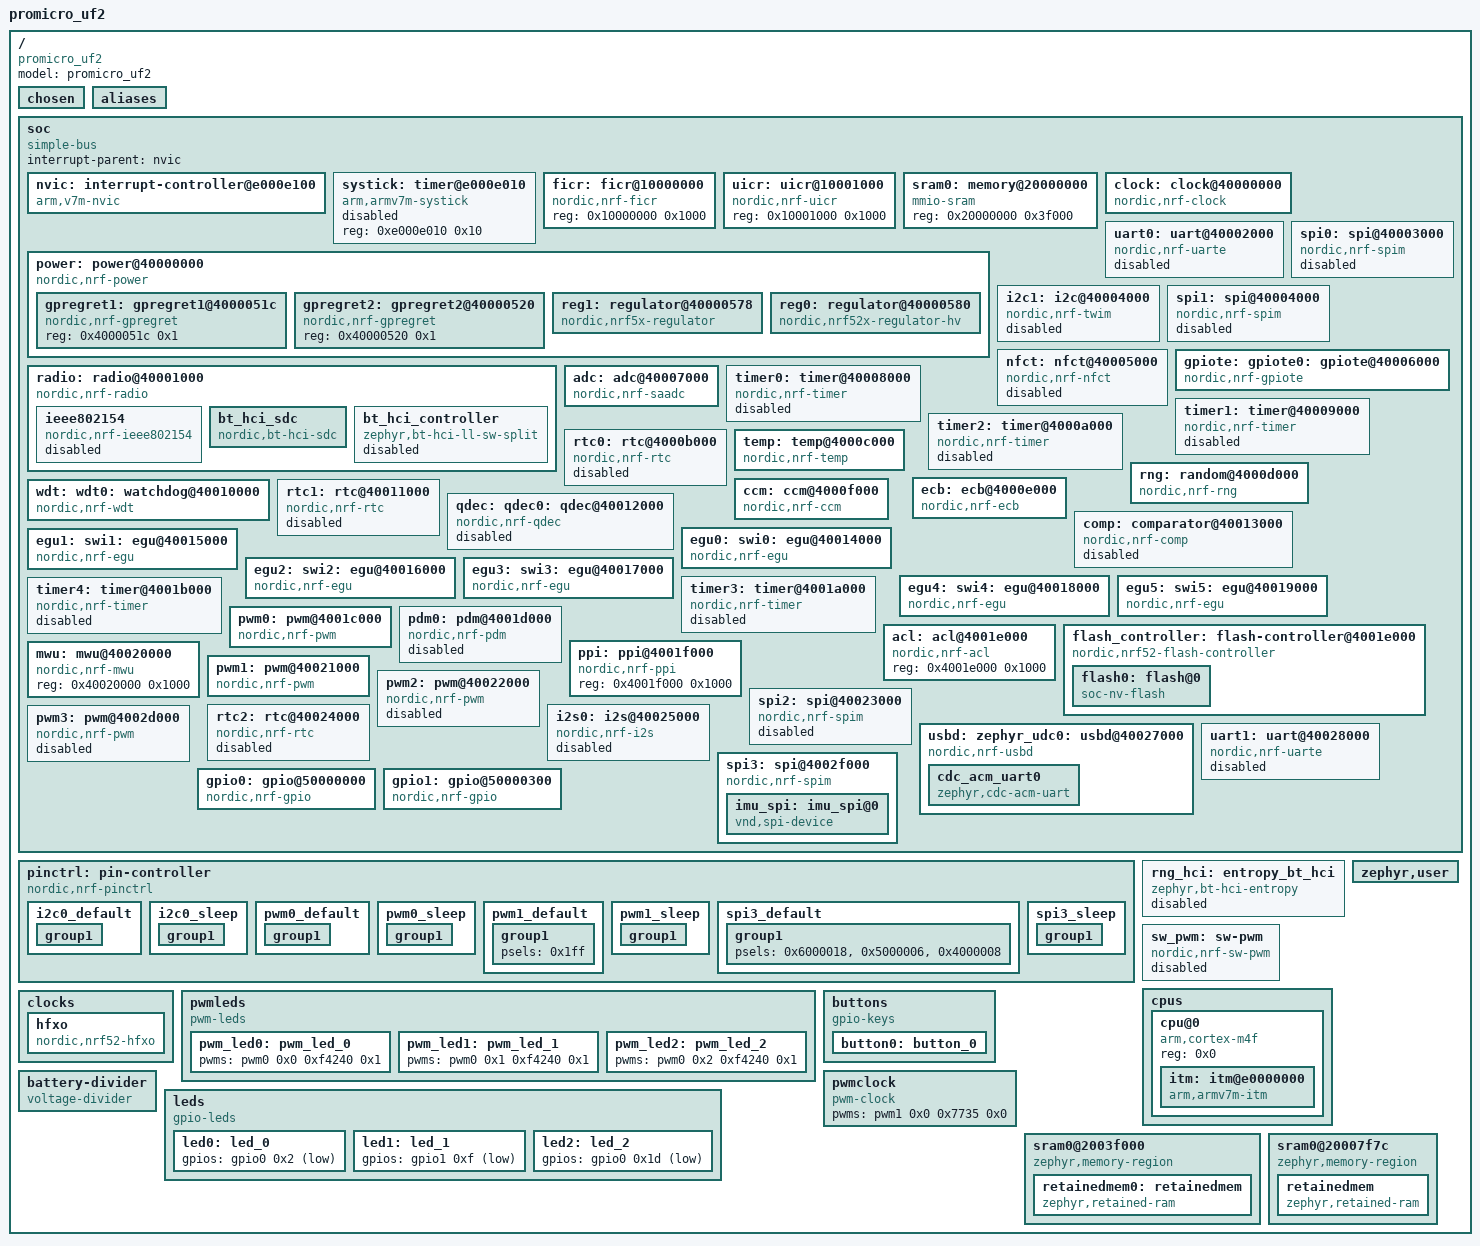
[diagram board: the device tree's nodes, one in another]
/dts-v1/;

/* node '/' defined in zephyr\dts\common\skeleton.dtsi:9 */
/ {
	#address-cells = < 0x1 >;    /* in zephyr\dts\common\skeleton.dtsi:10 */
	#size-cells = < 0x1 >;       /* in zephyr\dts\common\skeleton.dtsi:11 */
	model = "promicro_uf2";      /* in F:/nRF-Firmware-DqEdit/SlimeVR-Tracker-nRF/boards/nekumori/sakuranrf/sakuranrf_uf2.dts:71 */
	compatible = "promicro_uf2"; /* in F:/nRF-Firmware-DqEdit/SlimeVR-Tracker-nRF/boards/nekumori/sakuranrf/sakuranrf_uf2.dts:72 */

	/* node '/chosen' defined in zephyr\dts\common\skeleton.dtsi:12 */
	chosen {
		zephyr,bt-hci = &bt_hci_sdc;                 /* in zephyr\dts\arm\nordic\nrf52833.dtsi:14 */
		zephyr,entropy = &rng;                       /* in zephyr\dts\arm\nordic\nrf52833.dtsi:15 */
		zephyr,flash-controller = &flash_controller; /* in zephyr\dts\arm\nordic\nrf52833.dtsi:16 */
		zephyr,sram = &sram0;                        /* in F:/nRF-Firmware-DqEdit/SlimeVR-Tracker-nRF/boards/nekumori/sakuranrf/sakuranrf_uf2.dts:75 */
		zephyr,flash = &flash0;                      /* in F:/nRF-Firmware-DqEdit/SlimeVR-Tracker-nRF/boards/nekumori/sakuranrf/sakuranrf_uf2.dts:76 */
		zephyr,console = &cdc_acm_uart0;             /* in F:/nRF-Firmware-DqEdit/SlimeVR-Tracker-nRF/boards/nekumori/sakuranrf/sakuranrf_uf2.dts:77 */
		zephyr,shell-uart = &cdc_acm_uart0;          /* in F:/nRF-Firmware-DqEdit/SlimeVR-Tracker-nRF/boards/nekumori/sakuranrf/sakuranrf_uf2.dts:78 */
	};

	/* node '/aliases' defined in zephyr\dts\common\skeleton.dtsi:13 */
	aliases {
		sw0 = &button0;                    /* in F:/nRF-Firmware-DqEdit/SlimeVR-Tracker-nRF/boards/nekumori/sakuranrf/sakuranrf_uf2_chrysalis.dts:54 */
		pwm-led0 = &pwm_led0;              /* in F:/nRF-Firmware-DqEdit/SlimeVR-Tracker-nRF/boards/nekumori/sakuranrf/sakuranrf_uf2_chrysalis.dts:55 */
		pwm-led1 = &pwm_led1;              /* in F:/nRF-Firmware-DqEdit/SlimeVR-Tracker-nRF/boards/nekumori/sakuranrf/sakuranrf_uf2_chrysalis.dts:56 */
		pwm-led2 = &pwm_led2;              /* in F:/nRF-Firmware-DqEdit/SlimeVR-Tracker-nRF/boards/nekumori/sakuranrf/sakuranrf_uf2_chrysalis.dts:57 */
		led0 = &led0;                      /* in F:/nRF-Firmware-DqEdit/SlimeVR-Tracker-nRF/boards/nekumori/sakuranrf/sakuranrf_uf2_chrysalis.dts:58 */
		led1 = &led1;                      /* in F:/nRF-Firmware-DqEdit/SlimeVR-Tracker-nRF/boards/nekumori/sakuranrf/sakuranrf_uf2_chrysalis.dts:59 */
		led2 = &led2;                      /* in F:/nRF-Firmware-DqEdit/SlimeVR-Tracker-nRF/boards/nekumori/sakuranrf/sakuranrf_uf2_chrysalis.dts:60 */
		retainedmemdevice = &retainedmem0; /* in F:/nRF-Firmware-DqEdit/SlimeVR-Tracker-nRF/socs/nrf52833_chrysalis.overlay:27 */
	};

	/* node '/soc' defined in zephyr\dts\arm\armv7-m.dtsi:6 */
	soc {
		#address-cells = < 0x1 >;     /* in zephyr\dts\arm\armv7-m.dtsi:7 */
		#size-cells = < 0x1 >;        /* in zephyr\dts\arm\armv7-m.dtsi:8 */
		interrupt-parent = < &nvic >; /* in zephyr\dts\arm\armv7-m.dtsi:10 */
		ranges;                       /* in zephyr\dts\arm\armv7-m.dtsi:11 */
		compatible = "simple-bus";    /* in zephyr\dts\arm\nordic\nrf52833_qiaa.dtsi:20 */

		/* node '/soc/interrupt-controller@e000e100' defined in zephyr\dts\arm\armv7-m.dtsi:13 */
		nvic: interrupt-controller@e000e100 {
			#address-cells = < 0x1 >;            /* in zephyr\dts\arm\armv7-m.dtsi:14 */
			compatible = "arm,v7m-nvic";         /* in zephyr\dts\arm\armv7-m.dtsi:15 */
			reg = < 0xe000e100 0xc00 >;          /* in zephyr\dts\arm\armv7-m.dtsi:16 */
			interrupt-controller;                /* in zephyr\dts\arm\armv7-m.dtsi:17 */
			#interrupt-cells = < 0x2 >;          /* in zephyr\dts\arm\armv7-m.dtsi:18 */
			arm,num-irq-priority-bits = < 0x3 >; /* in zephyr\dts\arm\nordic\nrf52833.dtsi:576 */
			phandle = < 0x1 >;                   /* in zephyr\dts\arm\armv7-m.dtsi:10 */
		};

		/* node '/soc/timer@e000e010' defined in zephyr\dts\arm\armv7-m.dtsi:21 */
		systick: timer@e000e010 {
			compatible = "arm,armv7m-systick"; /* in zephyr\dts\arm\armv7-m.dtsi:22 */
			reg = < 0xe000e010 0x10 >;         /* in zephyr\dts\arm\armv7-m.dtsi:23 */
			status = "disabled";               /* in zephyr\dts\arm\nordic\nrf52833.dtsi:581 */
		};

		/* node '/soc/ficr@10000000' defined in zephyr\dts\arm\nordic\nrf52833.dtsi:48 */
		ficr: ficr@10000000 {
			compatible = "nordic,nrf-ficr"; /* in zephyr\dts\arm\nordic\nrf52833.dtsi:49 */
			reg = < 0x10000000 0x1000 >;    /* in zephyr\dts\arm\nordic\nrf52833.dtsi:50 */
			#nordic,ficr-cells = < 0x1 >;   /* in zephyr\dts\arm\nordic\nrf52833.dtsi:51 */
			status = "okay";                /* in zephyr\dts\arm\nordic\nrf52833.dtsi:52 */
		};

		/* node '/soc/uicr@10001000' defined in zephyr\dts\arm\nordic\nrf52833.dtsi:55 */
		uicr: uicr@10001000 {
			compatible = "nordic,nrf-uicr"; /* in zephyr\dts\arm\nordic\nrf52833.dtsi:56 */
			reg = < 0x10001000 0x1000 >;    /* in zephyr\dts\arm\nordic\nrf52833.dtsi:57 */
			status = "okay";                /* in zephyr\dts\arm\nordic\nrf52833.dtsi:58 */
		};

		/* node '/soc/memory@20000000' defined in zephyr\dts\arm\nordic\nrf52833.dtsi:61 */
		sram0: memory@20000000 {
			compatible = "mmio-sram";     /* in zephyr\dts\arm\nordic\nrf52833.dtsi:62 */
			reg = < 0x20000000 0x3f000 >; /* in F:/nRF-Firmware-DqEdit/SlimeVR-Tracker-nRF/socs/nrf52833_chrysalis.overlay:33 */
		};

		/* node '/soc/clock@40000000' defined in zephyr\dts\arm\nordic\nrf52833.dtsi:65 */
		clock: clock@40000000 {
			compatible = "nordic,nrf-clock"; /* in zephyr\dts\arm\nordic\nrf52833.dtsi:66 */
			reg = < 0x40000000 0x1000 >;     /* in zephyr\dts\arm\nordic\nrf52833.dtsi:67 */
			interrupts = < 0x0 0x1 >;        /* in zephyr\dts\arm\nordic\nrf52833.dtsi:68 */
			status = "okay";                 /* in zephyr\dts\arm\nordic\nrf52833.dtsi:69 */
		};

		/* node '/soc/power@40000000' defined in zephyr\dts\arm\nordic\nrf52833.dtsi:72 */
		power: power@40000000 {
			compatible = "nordic,nrf-power"; /* in zephyr\dts\arm\nordic\nrf52833.dtsi:73 */
			reg = < 0x40000000 0x1000 >;     /* in zephyr\dts\arm\nordic\nrf52833.dtsi:74 */
			interrupts = < 0x0 0x1 >;        /* in zephyr\dts\arm\nordic\nrf52833.dtsi:75 */
			status = "okay";                 /* in zephyr\dts\arm\nordic\nrf52833.dtsi:76 */
			#address-cells = < 0x1 >;        /* in zephyr\dts\arm\nordic\nrf52833.dtsi:77 */
			#size-cells = < 0x1 >;           /* in zephyr\dts\arm\nordic\nrf52833.dtsi:78 */

			/* node '/soc/power@40000000/gpregret1@4000051c' defined in zephyr\dts\arm\nordic\nrf52833.dtsi:80 */
			gpregret1: gpregret1@4000051c {
				#address-cells = < 0x1 >;           /* in zephyr\dts\arm\nordic\nrf52833.dtsi:81 */
				#size-cells = < 0x1 >;              /* in zephyr\dts\arm\nordic\nrf52833.dtsi:82 */
				compatible = "nordic,nrf-gpregret"; /* in zephyr\dts\arm\nordic\nrf52833.dtsi:83 */
				reg = < 0x4000051c 0x1 >;           /* in zephyr\dts\arm\nordic\nrf52833.dtsi:84 */
				status = "okay";                    /* in zephyr\dts\arm\nordic\nrf52833.dtsi:85 */
			};

			/* node '/soc/power@40000000/gpregret2@40000520' defined in zephyr\dts\arm\nordic\nrf52833.dtsi:88 */
			gpregret2: gpregret2@40000520 {
				#address-cells = < 0x1 >;           /* in zephyr\dts\arm\nordic\nrf52833.dtsi:89 */
				#size-cells = < 0x1 >;              /* in zephyr\dts\arm\nordic\nrf52833.dtsi:90 */
				compatible = "nordic,nrf-gpregret"; /* in zephyr\dts\arm\nordic\nrf52833.dtsi:91 */
				reg = < 0x40000520 0x1 >;           /* in zephyr\dts\arm\nordic\nrf52833.dtsi:92 */
				status = "okay";                    /* in zephyr\dts\arm\nordic\nrf52833.dtsi:93 */
			};

			/* node '/soc/power@40000000/regulator@40000578' defined in zephyr\dts\arm\nordic\nrf52833.dtsi:96 */
			reg1: regulator@40000578 {
				compatible = "nordic,nrf5x-regulator"; /* in zephyr\dts\arm\nordic\nrf52833.dtsi:97 */
				reg = < 0x40000578 0x1 >;              /* in zephyr\dts\arm\nordic\nrf52833.dtsi:98 */
				regulator-name = "REG1";               /* in zephyr\dts\arm\nordic\nrf52833.dtsi:99 */
				regulator-initial-mode = < 0x1 >;      /* in F:/nRF-Firmware-DqEdit/SlimeVR-Tracker-nRF/boards/nekumori/sakuranrf/sakuranrf_uf2.dts:129 */
			};

			/* node '/soc/power@40000000/regulator@40000580' defined in zephyr\dts\arm\nordic\nrf52833.dtsi:103 */
			reg0: regulator@40000580 {
				compatible = "nordic,nrf52x-regulator-hv"; /* in zephyr\dts\arm\nordic\nrf52833.dtsi:104 */
				reg = < 0x40000580 0x1 >;                  /* in zephyr\dts\arm\nordic\nrf52833.dtsi:105 */
				regulator-name = "REG0";                   /* in zephyr\dts\arm\nordic\nrf52833.dtsi:106 */
				status = "okay";                           /* in F:/nRF-Firmware-DqEdit/SlimeVR-Tracker-nRF/boards/nekumori/sakuranrf/sakuranrf_uf2.dts:125 */
			};
		};

		/* node '/soc/radio@40001000' defined in zephyr\dts\arm\nordic\nrf52833.dtsi:111 */
		radio: radio@40001000 {
			compatible = "nordic,nrf-radio"; /* in zephyr\dts\arm\nordic\nrf52833.dtsi:112 */
			reg = < 0x40001000 0x1000 >;     /* in zephyr\dts\arm\nordic\nrf52833.dtsi:113 */
			interrupts = < 0x1 0x1 >;        /* in zephyr\dts\arm\nordic\nrf52833.dtsi:114 */
			status = "okay";                 /* in zephyr\dts\arm\nordic\nrf52833.dtsi:115 */
			dfe-supported;                   /* in zephyr\dts\arm\nordic\nrf52833.dtsi:116 */
			ieee802154-supported;            /* in zephyr\dts\arm\nordic\nrf52833.dtsi:117 */
			ble-2mbps-supported;             /* in zephyr\dts\arm\nordic\nrf52833.dtsi:118 */
			ble-coded-phy-supported;         /* in zephyr\dts\arm\nordic\nrf52833.dtsi:119 */
			tx-high-power-supported;         /* in zephyr\dts\arm\nordic\nrf52833.dtsi:120 */

			/* node '/soc/radio@40001000/ieee802154' defined in zephyr\dts\arm\nordic\nrf52833.dtsi:122 */
			ieee802154: ieee802154 {
				compatible = "nordic,nrf-ieee802154"; /* in zephyr\dts\arm\nordic\nrf52833.dtsi:123 */
				status = "disabled";                  /* in zephyr\dts\arm\nordic\nrf52833.dtsi:124 */
			};

			/* node '/soc/radio@40001000/bt_hci_sdc' defined in zephyr\dts\arm\nordic\nrf52833.dtsi:127 */
			bt_hci_sdc: bt_hci_sdc {
				compatible = "nordic,bt-hci-sdc"; /* in zephyr\dts\arm\nordic\nrf52833.dtsi:128 */
				status = "okay";                  /* in zephyr\dts\arm\nordic\nrf52833.dtsi:129 */
			};

			/* node '/soc/radio@40001000/bt_hci_controller' defined in zephyr\dts\arm\nordic\nrf52833.dtsi:131 */
			bt_hci_controller: bt_hci_controller {
				compatible = "zephyr,bt-hci-ll-sw-split"; /* in zephyr\dts\arm\nordic\nrf52833.dtsi:132 */
				status = "disabled";                      /* in zephyr\dts\arm\nordic\nrf52833.dtsi:133 */
			};
		};

		/* node '/soc/uart@40002000' defined in zephyr\dts\arm\nordic\nrf52833.dtsi:137 */
		uart0: uart@40002000 {
			compatible = "nordic,nrf-uarte"; /* in zephyr\dts\arm\nordic\nrf52833.dtsi:140 */
			reg = < 0x40002000 0x1000 >;     /* in zephyr\dts\arm\nordic\nrf52833.dtsi:141 */
			interrupts = < 0x2 0x1 >;        /* in zephyr\dts\arm\nordic\nrf52833.dtsi:142 */
			status = "disabled";             /* in zephyr\dts\arm\nordic\nrf52833.dtsi:143 */
		};

		/* node '/soc/spi@40003000' defined in zephyr\dts\arm\nordic\nrf52833.dtsi:164 */
		spi0: spi@40003000 {
			compatible = "nordic,nrf-spim"; /* in zephyr\dts\arm\nordic\nrf52833.dtsi:172 */
			#address-cells = < 0x1 >;       /* in zephyr\dts\arm\nordic\nrf52833.dtsi:173 */
			#size-cells = < 0x0 >;          /* in zephyr\dts\arm\nordic\nrf52833.dtsi:174 */
			reg = < 0x40003000 0x1000 >;    /* in zephyr\dts\arm\nordic\nrf52833.dtsi:175 */
			interrupts = < 0x3 0x1 >;       /* in zephyr\dts\arm\nordic\nrf52833.dtsi:176 */
			max-frequency = < 0x7a1200 >;   /* in zephyr\dts\arm\nordic\nrf52833.dtsi:177 */
			easydma-maxcnt-bits = < 0x10 >; /* in zephyr\dts\arm\nordic\nrf52833.dtsi:178 */
			status = "disabled";            /* in zephyr\dts\arm\nordic\nrf52833.dtsi:179 */
		};

		/* node '/soc/i2c@40004000' defined in zephyr\dts\arm\nordic\nrf52833.dtsi:182 */
		i2c1: i2c@40004000 {
			compatible = "nordic,nrf-twim"; /* in zephyr\dts\arm\nordic\nrf52833.dtsi:190 */
			#address-cells = < 0x1 >;       /* in zephyr\dts\arm\nordic\nrf52833.dtsi:191 */
			#size-cells = < 0x0 >;          /* in zephyr\dts\arm\nordic\nrf52833.dtsi:192 */
			reg = < 0x40004000 0x1000 >;    /* in zephyr\dts\arm\nordic\nrf52833.dtsi:193 */
			interrupts = < 0x4 0x1 >;       /* in zephyr\dts\arm\nordic\nrf52833.dtsi:194 */
			easydma-maxcnt-bits = < 0x10 >; /* in zephyr\dts\arm\nordic\nrf52833.dtsi:195 */
			status = "disabled";            /* in zephyr\dts\arm\nordic\nrf52833.dtsi:196 */
			zephyr,pm-device-runtime-auto;  /* in zephyr\dts\arm\nordic\nrf52833.dtsi:197 */
		};

		/* node '/soc/spi@40004000' defined in zephyr\dts\arm\nordic\nrf52833.dtsi:200 */
		spi1: spi@40004000 {
			compatible = "nordic,nrf-spim"; /* in zephyr\dts\arm\nordic\nrf52833.dtsi:208 */
			#address-cells = < 0x1 >;       /* in zephyr\dts\arm\nordic\nrf52833.dtsi:209 */
			#size-cells = < 0x0 >;          /* in zephyr\dts\arm\nordic\nrf52833.dtsi:210 */
			reg = < 0x40004000 0x1000 >;    /* in zephyr\dts\arm\nordic\nrf52833.dtsi:211 */
			interrupts = < 0x4 0x1 >;       /* in zephyr\dts\arm\nordic\nrf52833.dtsi:212 */
			max-frequency = < 0x7a1200 >;   /* in zephyr\dts\arm\nordic\nrf52833.dtsi:213 */
			easydma-maxcnt-bits = < 0x10 >; /* in zephyr\dts\arm\nordic\nrf52833.dtsi:214 */
			status = "disabled";            /* in zephyr\dts\arm\nordic\nrf52833.dtsi:215 */
		};

		/* node '/soc/nfct@40005000' defined in zephyr\dts\arm\nordic\nrf52833.dtsi:218 */
		nfct: nfct@40005000 {
			compatible = "nordic,nrf-nfct"; /* in zephyr\dts\arm\nordic\nrf52833.dtsi:219 */
			reg = < 0x40005000 0x1000 >;    /* in zephyr\dts\arm\nordic\nrf52833.dtsi:220 */
			interrupts = < 0x5 0x1 >;       /* in zephyr\dts\arm\nordic\nrf52833.dtsi:221 */
			status = "disabled";            /* in F:/nRF-Firmware-DqEdit/SlimeVR-Tracker-nRF/boards/nekumori/sakuranrf/sakuranrf_uf2.dts:199 */
		};

		/* node '/soc/gpiote@40006000' defined in zephyr\dts\arm\nordic\nrf52833.dtsi:225 */
		gpiote: gpiote0: gpiote@40006000 {
			compatible = "nordic,nrf-gpiote"; /* in zephyr\dts\arm\nordic\nrf52833.dtsi:226 */
			reg = < 0x40006000 0x1000 >;      /* in zephyr\dts\arm\nordic\nrf52833.dtsi:227 */
			interrupts = < 0x6 0x5 >;         /* in zephyr\dts\arm\nordic\nrf52833.dtsi:228 */
			instance = < 0x0 >;               /* in zephyr\dts\arm\nordic\nrf52833.dtsi:230 */
			status = "okay";                  /* in F:/nRF-Firmware-DqEdit/SlimeVR-Tracker-nRF/boards/nekumori/sakuranrf/sakuranrf_uf2.dts:137 */
			phandle = < 0x9 >;                /* in zephyr\dts\arm\nordic\nrf52833.dtsi:558 */
		};

		/* node '/soc/adc@40007000' defined in zephyr\dts\arm\nordic\nrf52833.dtsi:233 */
		adc: adc@40007000 {
			compatible = "nordic,nrf-saadc"; /* in zephyr\dts\arm\nordic\nrf52833.dtsi:234 */
			reg = < 0x40007000 0x1000 >;     /* in zephyr\dts\arm\nordic\nrf52833.dtsi:235 */
			interrupts = < 0x7 0x1 >;        /* in zephyr\dts\arm\nordic\nrf52833.dtsi:236 */
			#io-channel-cells = < 0x1 >;     /* in zephyr\dts\arm\nordic\nrf52833.dtsi:238 */
			zephyr,pm-device-runtime-auto;   /* in zephyr\dts\arm\nordic\nrf52833.dtsi:239 */
			status = "okay";                 /* in F:/nRF-Firmware-DqEdit/SlimeVR-Tracker-nRF/boards/nekumori/sakuranrf/sakuranrf_uf2.dts:133 */
			phandle = < 0xe >;               /* in F:/nRF-Firmware-DqEdit/SlimeVR-Tracker-nRF/boards/nekumori/sakuranrf/sakuranrf_uf2.dts:110 */
		};

		/* node '/soc/timer@40008000' defined in zephyr\dts\arm\nordic\nrf52833.dtsi:242 */
		timer0: timer@40008000 {
			compatible = "nordic,nrf-timer"; /* in zephyr\dts\arm\nordic\nrf52833.dtsi:243 */
			status = "disabled";             /* in zephyr\dts\arm\nordic\nrf52833.dtsi:244 */
			reg = < 0x40008000 0x1000 >;     /* in zephyr\dts\arm\nordic\nrf52833.dtsi:245 */
			cc-num = < 0x4 >;                /* in zephyr\dts\arm\nordic\nrf52833.dtsi:246 */
			max-bit-width = < 0x20 >;        /* in zephyr\dts\arm\nordic\nrf52833.dtsi:247 */
			interrupts = < 0x8 0x1 >;        /* in zephyr\dts\arm\nordic\nrf52833.dtsi:248 */
			prescaler = < 0x0 >;             /* in zephyr\dts\arm\nordic\nrf52833.dtsi:249 */
		};

		/* node '/soc/timer@40009000' defined in zephyr\dts\arm\nordic\nrf52833.dtsi:252 */
		timer1: timer@40009000 {
			compatible = "nordic,nrf-timer"; /* in zephyr\dts\arm\nordic\nrf52833.dtsi:253 */
			status = "disabled";             /* in zephyr\dts\arm\nordic\nrf52833.dtsi:254 */
			reg = < 0x40009000 0x1000 >;     /* in zephyr\dts\arm\nordic\nrf52833.dtsi:255 */
			cc-num = < 0x4 >;                /* in zephyr\dts\arm\nordic\nrf52833.dtsi:256 */
			max-bit-width = < 0x20 >;        /* in zephyr\dts\arm\nordic\nrf52833.dtsi:257 */
			interrupts = < 0x9 0x1 >;        /* in zephyr\dts\arm\nordic\nrf52833.dtsi:258 */
			prescaler = < 0x0 >;             /* in zephyr\dts\arm\nordic\nrf52833.dtsi:259 */
			phandle = < 0xa >;               /* in zephyr\dts\vendor\nordic\nrf_common.dtsi:42 */
		};

		/* node '/soc/timer@4000a000' defined in zephyr\dts\arm\nordic\nrf52833.dtsi:262 */
		timer2: timer@4000a000 {
			compatible = "nordic,nrf-timer"; /* in zephyr\dts\arm\nordic\nrf52833.dtsi:263 */
			status = "disabled";             /* in zephyr\dts\arm\nordic\nrf52833.dtsi:264 */
			reg = < 0x4000a000 0x1000 >;     /* in zephyr\dts\arm\nordic\nrf52833.dtsi:265 */
			cc-num = < 0x4 >;                /* in zephyr\dts\arm\nordic\nrf52833.dtsi:266 */
			max-bit-width = < 0x20 >;        /* in zephyr\dts\arm\nordic\nrf52833.dtsi:267 */
			interrupts = < 0xa 0x1 >;        /* in zephyr\dts\arm\nordic\nrf52833.dtsi:268 */
			prescaler = < 0x0 >;             /* in zephyr\dts\arm\nordic\nrf52833.dtsi:269 */
		};

		/* node '/soc/rtc@4000b000' defined in zephyr\dts\arm\nordic\nrf52833.dtsi:272 */
		rtc0: rtc@4000b000 {
			compatible = "nordic,nrf-rtc"; /* in zephyr\dts\arm\nordic\nrf52833.dtsi:273 */
			reg = < 0x4000b000 0x1000 >;   /* in zephyr\dts\arm\nordic\nrf52833.dtsi:274 */
			cc-num = < 0x3 >;              /* in zephyr\dts\arm\nordic\nrf52833.dtsi:275 */
			interrupts = < 0xb 0x1 >;      /* in zephyr\dts\arm\nordic\nrf52833.dtsi:276 */
			status = "disabled";           /* in zephyr\dts\arm\nordic\nrf52833.dtsi:277 */
			clock-frequency = < 0x8000 >;  /* in zephyr\dts\arm\nordic\nrf52833.dtsi:278 */
			prescaler = < 0x1 >;           /* in zephyr\dts\arm\nordic\nrf52833.dtsi:279 */
		};

		/* node '/soc/temp@4000c000' defined in zephyr\dts\arm\nordic\nrf52833.dtsi:282 */
		temp: temp@4000c000 {
			compatible = "nordic,nrf-temp"; /* in zephyr\dts\arm\nordic\nrf52833.dtsi:283 */
			reg = < 0x4000c000 0x1000 >;    /* in zephyr\dts\arm\nordic\nrf52833.dtsi:284 */
			interrupts = < 0xc 0x1 >;       /* in zephyr\dts\arm\nordic\nrf52833.dtsi:285 */
			status = "okay";                /* in zephyr\dts\arm\nordic\nrf52833.dtsi:286 */
		};

		/* node '/soc/random@4000d000' defined in zephyr\dts\arm\nordic\nrf52833.dtsi:289 */
		rng: random@4000d000 {
			compatible = "nordic,nrf-rng"; /* in zephyr\dts\arm\nordic\nrf52833.dtsi:290 */
			reg = < 0x4000d000 0x1000 >;   /* in zephyr\dts\arm\nordic\nrf52833.dtsi:291 */
			interrupts = < 0xd 0x1 >;      /* in zephyr\dts\arm\nordic\nrf52833.dtsi:292 */
			status = "okay";               /* in zephyr\dts\arm\nordic\nrf52833.dtsi:293 */
		};

		/* node '/soc/ecb@4000e000' defined in zephyr\dts\arm\nordic\nrf52833.dtsi:296 */
		ecb: ecb@4000e000 {
			compatible = "nordic,nrf-ecb"; /* in zephyr\dts\arm\nordic\nrf52833.dtsi:297 */
			reg = < 0x4000e000 0x1000 >;   /* in zephyr\dts\arm\nordic\nrf52833.dtsi:298 */
			interrupts = < 0xe 0x1 >;      /* in zephyr\dts\arm\nordic\nrf52833.dtsi:299 */
			status = "okay";               /* in zephyr\dts\arm\nordic\nrf52833.dtsi:300 */
		};

		/* node '/soc/ccm@4000f000' defined in zephyr\dts\arm\nordic\nrf52833.dtsi:303 */
		ccm: ccm@4000f000 {
			compatible = "nordic,nrf-ccm"; /* in zephyr\dts\arm\nordic\nrf52833.dtsi:304 */
			reg = < 0x4000f000 0x1000 >;   /* in zephyr\dts\arm\nordic\nrf52833.dtsi:305 */
			interrupts = < 0xf 0x1 >;      /* in zephyr\dts\arm\nordic\nrf52833.dtsi:306 */
			length-field-length-8-bits;    /* in zephyr\dts\arm\nordic\nrf52833.dtsi:307 */
			headermask-supported;          /* in zephyr\dts\arm\nordic\nrf52833.dtsi:308 */
			status = "okay";               /* in zephyr\dts\arm\nordic\nrf52833.dtsi:309 */
		};

		/* node '/soc/watchdog@40010000' defined in zephyr\dts\arm\nordic\nrf52833.dtsi:312 */
		wdt: wdt0: watchdog@40010000 {
			compatible = "nordic,nrf-wdt"; /* in zephyr\dts\arm\nordic\nrf52833.dtsi:313 */
			reg = < 0x40010000 0x1000 >;   /* in zephyr\dts\arm\nordic\nrf52833.dtsi:314 */
			interrupts = < 0x10 0x1 >;     /* in zephyr\dts\arm\nordic\nrf52833.dtsi:315 */
			status = "okay";               /* in zephyr\dts\arm\nordic\nrf52833.dtsi:316 */
		};

		/* node '/soc/rtc@40011000' defined in zephyr\dts\arm\nordic\nrf52833.dtsi:319 */
		rtc1: rtc@40011000 {
			compatible = "nordic,nrf-rtc"; /* in zephyr\dts\arm\nordic\nrf52833.dtsi:320 */
			reg = < 0x40011000 0x1000 >;   /* in zephyr\dts\arm\nordic\nrf52833.dtsi:321 */
			cc-num = < 0x4 >;              /* in zephyr\dts\arm\nordic\nrf52833.dtsi:322 */
			interrupts = < 0x11 0x1 >;     /* in zephyr\dts\arm\nordic\nrf52833.dtsi:323 */
			status = "disabled";           /* in zephyr\dts\arm\nordic\nrf52833.dtsi:324 */
			clock-frequency = < 0x8000 >;  /* in zephyr\dts\arm\nordic\nrf52833.dtsi:325 */
			prescaler = < 0x1 >;           /* in zephyr\dts\arm\nordic\nrf52833.dtsi:326 */
		};

		/* node '/soc/qdec@40012000' defined in zephyr\dts\arm\nordic\nrf52833.dtsi:329 */
		qdec: qdec0: qdec@40012000 {
			compatible = "nordic,nrf-qdec"; /* in zephyr\dts\arm\nordic\nrf52833.dtsi:330 */
			reg = < 0x40012000 0x1000 >;    /* in zephyr\dts\arm\nordic\nrf52833.dtsi:331 */
			interrupts = < 0x12 0x1 >;      /* in zephyr\dts\arm\nordic\nrf52833.dtsi:332 */
			status = "disabled";            /* in zephyr\dts\arm\nordic\nrf52833.dtsi:333 */
		};

		/* node '/soc/comparator@40013000' defined in zephyr\dts\arm\nordic\nrf52833.dtsi:336 */
		comp: comparator@40013000 {
			compatible = "nordic,nrf-comp"; /* in zephyr\dts\arm\nordic\nrf52833.dtsi:341 */
			reg = < 0x40013000 0x1000 >;    /* in zephyr\dts\arm\nordic\nrf52833.dtsi:342 */
			interrupts = < 0x13 0x1 >;      /* in zephyr\dts\arm\nordic\nrf52833.dtsi:343 */
			status = "disabled";            /* in zephyr\dts\arm\nordic\nrf52833.dtsi:344 */
		};

		/* node '/soc/egu@40014000' defined in zephyr\dts\arm\nordic\nrf52833.dtsi:347 */
		egu0: swi0: egu@40014000 {
			compatible = "nordic,nrf-egu",
			             "nordic,nrf-swi"; /* in zephyr\dts\arm\nordic\nrf52833.dtsi:348 */
			reg = < 0x40014000 0x1000 >;   /* in zephyr\dts\arm\nordic\nrf52833.dtsi:349 */
			interrupts = < 0x14 0x1 >;     /* in zephyr\dts\arm\nordic\nrf52833.dtsi:350 */
			status = "okay";               /* in zephyr\dts\arm\nordic\nrf52833.dtsi:351 */
		};

		/* node '/soc/egu@40015000' defined in zephyr\dts\arm\nordic\nrf52833.dtsi:354 */
		egu1: swi1: egu@40015000 {
			compatible = "nordic,nrf-egu",
			             "nordic,nrf-swi"; /* in zephyr\dts\arm\nordic\nrf52833.dtsi:355 */
			reg = < 0x40015000 0x1000 >;   /* in zephyr\dts\arm\nordic\nrf52833.dtsi:356 */
			interrupts = < 0x15 0x1 >;     /* in zephyr\dts\arm\nordic\nrf52833.dtsi:357 */
			status = "okay";               /* in zephyr\dts\arm\nordic\nrf52833.dtsi:358 */
		};

		/* node '/soc/egu@40016000' defined in zephyr\dts\arm\nordic\nrf52833.dtsi:361 */
		egu2: swi2: egu@40016000 {
			compatible = "nordic,nrf-egu",
			             "nordic,nrf-swi"; /* in zephyr\dts\arm\nordic\nrf52833.dtsi:362 */
			reg = < 0x40016000 0x1000 >;   /* in zephyr\dts\arm\nordic\nrf52833.dtsi:363 */
			interrupts = < 0x16 0x1 >;     /* in zephyr\dts\arm\nordic\nrf52833.dtsi:364 */
			status = "okay";               /* in zephyr\dts\arm\nordic\nrf52833.dtsi:365 */
		};

		/* node '/soc/egu@40017000' defined in zephyr\dts\arm\nordic\nrf52833.dtsi:368 */
		egu3: swi3: egu@40017000 {
			compatible = "nordic,nrf-egu",
			             "nordic,nrf-swi"; /* in zephyr\dts\arm\nordic\nrf52833.dtsi:369 */
			reg = < 0x40017000 0x1000 >;   /* in zephyr\dts\arm\nordic\nrf52833.dtsi:370 */
			interrupts = < 0x17 0x1 >;     /* in zephyr\dts\arm\nordic\nrf52833.dtsi:371 */
			status = "okay";               /* in zephyr\dts\arm\nordic\nrf52833.dtsi:372 */
		};

		/* node '/soc/egu@40018000' defined in zephyr\dts\arm\nordic\nrf52833.dtsi:375 */
		egu4: swi4: egu@40018000 {
			compatible = "nordic,nrf-egu",
			             "nordic,nrf-swi"; /* in zephyr\dts\arm\nordic\nrf52833.dtsi:376 */
			reg = < 0x40018000 0x1000 >;   /* in zephyr\dts\arm\nordic\nrf52833.dtsi:377 */
			interrupts = < 0x18 0x1 >;     /* in zephyr\dts\arm\nordic\nrf52833.dtsi:378 */
			status = "okay";               /* in zephyr\dts\arm\nordic\nrf52833.dtsi:379 */
		};

		/* node '/soc/egu@40019000' defined in zephyr\dts\arm\nordic\nrf52833.dtsi:382 */
		egu5: swi5: egu@40019000 {
			compatible = "nordic,nrf-egu",
			             "nordic,nrf-swi"; /* in zephyr\dts\arm\nordic\nrf52833.dtsi:383 */
			reg = < 0x40019000 0x1000 >;   /* in zephyr\dts\arm\nordic\nrf52833.dtsi:384 */
			interrupts = < 0x19 0x1 >;     /* in zephyr\dts\arm\nordic\nrf52833.dtsi:385 */
			status = "okay";               /* in zephyr\dts\arm\nordic\nrf52833.dtsi:386 */
		};

		/* node '/soc/timer@4001a000' defined in zephyr\dts\arm\nordic\nrf52833.dtsi:389 */
		timer3: timer@4001a000 {
			compatible = "nordic,nrf-timer"; /* in zephyr\dts\arm\nordic\nrf52833.dtsi:390 */
			status = "disabled";             /* in zephyr\dts\arm\nordic\nrf52833.dtsi:391 */
			reg = < 0x4001a000 0x1000 >;     /* in zephyr\dts\arm\nordic\nrf52833.dtsi:392 */
			cc-num = < 0x6 >;                /* in zephyr\dts\arm\nordic\nrf52833.dtsi:393 */
			max-bit-width = < 0x20 >;        /* in zephyr\dts\arm\nordic\nrf52833.dtsi:394 */
			interrupts = < 0x1a 0x1 >;       /* in zephyr\dts\arm\nordic\nrf52833.dtsi:395 */
			prescaler = < 0x0 >;             /* in zephyr\dts\arm\nordic\nrf52833.dtsi:396 */
		};

		/* node '/soc/timer@4001b000' defined in zephyr\dts\arm\nordic\nrf52833.dtsi:399 */
		timer4: timer@4001b000 {
			compatible = "nordic,nrf-timer"; /* in zephyr\dts\arm\nordic\nrf52833.dtsi:400 */
			status = "disabled";             /* in zephyr\dts\arm\nordic\nrf52833.dtsi:401 */
			reg = < 0x4001b000 0x1000 >;     /* in zephyr\dts\arm\nordic\nrf52833.dtsi:402 */
			cc-num = < 0x6 >;                /* in zephyr\dts\arm\nordic\nrf52833.dtsi:403 */
			max-bit-width = < 0x20 >;        /* in zephyr\dts\arm\nordic\nrf52833.dtsi:404 */
			interrupts = < 0x1b 0x1 >;       /* in zephyr\dts\arm\nordic\nrf52833.dtsi:405 */
			prescaler = < 0x0 >;             /* in zephyr\dts\arm\nordic\nrf52833.dtsi:406 */
		};

		/* node '/soc/pwm@4001c000' defined in zephyr\dts\arm\nordic\nrf52833.dtsi:409 */
		pwm0: pwm@4001c000 {
			compatible = "nordic,nrf-pwm"; /* in zephyr\dts\arm\nordic\nrf52833.dtsi:410 */
			reg = < 0x4001c000 0x1000 >;   /* in zephyr\dts\arm\nordic\nrf52833.dtsi:411 */
			interrupts = < 0x1c 0x1 >;     /* in zephyr\dts\arm\nordic\nrf52833.dtsi:412 */
			#pwm-cells = < 0x3 >;          /* in zephyr\dts\arm\nordic\nrf52833.dtsi:414 */
			status = "okay";               /* in F:/nRF-Firmware-DqEdit/SlimeVR-Tracker-nRF/boards/nekumori/sakuranrf/sakuranrf_uf2.dts:173 */
			pinctrl-0 = < &pwm0_default >; /* in F:/nRF-Firmware-DqEdit/SlimeVR-Tracker-nRF/boards/nekumori/sakuranrf/sakuranrf_uf2.dts:174 */
			pinctrl-1 = < &pwm0_sleep >;   /* in F:/nRF-Firmware-DqEdit/SlimeVR-Tracker-nRF/boards/nekumori/sakuranrf/sakuranrf_uf2.dts:175 */
			pinctrl-names = "default",
			                "sleep";       /* in F:/nRF-Firmware-DqEdit/SlimeVR-Tracker-nRF/boards/nekumori/sakuranrf/sakuranrf_uf2.dts:176 */
			phandle = < 0xb >;             /* in F:/nRF-Firmware-DqEdit/SlimeVR-Tracker-nRF/boards/nekumori/sakuranrf/sakuranrf_uf2_chrysalis.dts:30 */
		};

		/* node '/soc/pdm@4001d000' defined in zephyr\dts\arm\nordic\nrf52833.dtsi:417 */
		pdm0: pdm@4001d000 {
			compatible = "nordic,nrf-pdm"; /* in zephyr\dts\arm\nordic\nrf52833.dtsi:418 */
			reg = < 0x4001d000 0x1000 >;   /* in zephyr\dts\arm\nordic\nrf52833.dtsi:419 */
			interrupts = < 0x1d 0x1 >;     /* in zephyr\dts\arm\nordic\nrf52833.dtsi:420 */
			status = "disabled";           /* in zephyr\dts\arm\nordic\nrf52833.dtsi:421 */
		};

		/* node '/soc/acl@4001e000' defined in zephyr\dts\arm\nordic\nrf52833.dtsi:424 */
		acl: acl@4001e000 {
			compatible = "nordic,nrf-acl"; /* in zephyr\dts\arm\nordic\nrf52833.dtsi:425 */
			reg = < 0x4001e000 0x1000 >;   /* in zephyr\dts\arm\nordic\nrf52833.dtsi:426 */
			status = "okay";               /* in zephyr\dts\arm\nordic\nrf52833.dtsi:427 */
		};

		/* node '/soc/flash-controller@4001e000' defined in zephyr\dts\arm\nordic\nrf52833.dtsi:430 */
		flash_controller: flash-controller@4001e000 {
			compatible = "nordic,nrf52-flash-controller"; /* in zephyr\dts\arm\nordic\nrf52833.dtsi:431 */
			reg = < 0x4001e000 0x1000 >;                  /* in zephyr\dts\arm\nordic\nrf52833.dtsi:432 */
			partial-erase;                                /* in zephyr\dts\arm\nordic\nrf52833.dtsi:433 */
			#address-cells = < 0x1 >;                     /* in zephyr\dts\arm\nordic\nrf52833.dtsi:435 */
			#size-cells = < 0x1 >;                        /* in zephyr\dts\arm\nordic\nrf52833.dtsi:436 */

			/* node '/soc/flash-controller@4001e000/flash@0' defined in zephyr\dts\arm\nordic\nrf52833.dtsi:438 */
			flash0: flash@0 {
				compatible = "soc-nv-flash";   /* in zephyr\dts\arm\nordic\nrf52833.dtsi:439 */
				erase-block-size = < 0x1000 >; /* in zephyr\dts\arm\nordic\nrf52833.dtsi:440 */
				write-block-size = < 0x4 >;    /* in zephyr\dts\arm\nordic\nrf52833.dtsi:441 */
				reg = < 0x0 0x80000 >;         /* in zephyr\dts\arm\nordic\nrf52833_qiaa.dtsi:11 */
			};
		};

		/* node '/soc/ppi@4001f000' defined in zephyr\dts\arm\nordic\nrf52833.dtsi:445 */
		ppi: ppi@4001f000 {
			compatible = "nordic,nrf-ppi"; /* in zephyr\dts\arm\nordic\nrf52833.dtsi:446 */
			reg = < 0x4001f000 0x1000 >;   /* in zephyr\dts\arm\nordic\nrf52833.dtsi:447 */
			status = "okay";               /* in zephyr\dts\arm\nordic\nrf52833.dtsi:448 */
		};

		/* node '/soc/mwu@40020000' defined in zephyr\dts\arm\nordic\nrf52833.dtsi:451 */
		mwu: mwu@40020000 {
			compatible = "nordic,nrf-mwu"; /* in zephyr\dts\arm\nordic\nrf52833.dtsi:452 */
			reg = < 0x40020000 0x1000 >;   /* in zephyr\dts\arm\nordic\nrf52833.dtsi:453 */
			status = "okay";               /* in zephyr\dts\arm\nordic\nrf52833.dtsi:454 */
		};

		/* node '/soc/pwm@40021000' defined in zephyr\dts\arm\nordic\nrf52833.dtsi:457 */
		pwm1: pwm@40021000 {
			compatible = "nordic,nrf-pwm"; /* in zephyr\dts\arm\nordic\nrf52833.dtsi:458 */
			reg = < 0x40021000 0x1000 >;   /* in zephyr\dts\arm\nordic\nrf52833.dtsi:459 */
			interrupts = < 0x21 0x1 >;     /* in zephyr\dts\arm\nordic\nrf52833.dtsi:460 */
			#pwm-cells = < 0x3 >;          /* in zephyr\dts\arm\nordic\nrf52833.dtsi:462 */
			status = "okay";               /* in F:/nRF-Firmware-DqEdit/SlimeVR-Tracker-nRF/boards/nekumori/sakuranrf/sakuranrf_uf2.dts:180 */
			pinctrl-0 = < &pwm1_default >; /* in F:/nRF-Firmware-DqEdit/SlimeVR-Tracker-nRF/boards/nekumori/sakuranrf/sakuranrf_uf2.dts:181 */
			pinctrl-1 = < &pwm1_sleep >;   /* in F:/nRF-Firmware-DqEdit/SlimeVR-Tracker-nRF/boards/nekumori/sakuranrf/sakuranrf_uf2.dts:182 */
			pinctrl-names = "default",
			                "sleep";       /* in F:/nRF-Firmware-DqEdit/SlimeVR-Tracker-nRF/boards/nekumori/sakuranrf/sakuranrf_uf2.dts:183 */
			phandle = < 0xd >;             /* in F:/nRF-Firmware-DqEdit/SlimeVR-Tracker-nRF/boards/nekumori/sakuranrf/sakuranrf_uf2.dts:104 */
		};

		/* node '/soc/pwm@40022000' defined in zephyr\dts\arm\nordic\nrf52833.dtsi:465 */
		pwm2: pwm@40022000 {
			compatible = "nordic,nrf-pwm"; /* in zephyr\dts\arm\nordic\nrf52833.dtsi:466 */
			reg = < 0x40022000 0x1000 >;   /* in zephyr\dts\arm\nordic\nrf52833.dtsi:467 */
			interrupts = < 0x22 0x1 >;     /* in zephyr\dts\arm\nordic\nrf52833.dtsi:468 */
			status = "disabled";           /* in zephyr\dts\arm\nordic\nrf52833.dtsi:469 */
			#pwm-cells = < 0x3 >;          /* in zephyr\dts\arm\nordic\nrf52833.dtsi:470 */
		};

		/* node '/soc/spi@40023000' defined in zephyr\dts\arm\nordic\nrf52833.dtsi:473 */
		spi2: spi@40023000 {
			compatible = "nordic,nrf-spim"; /* in zephyr\dts\arm\nordic\nrf52833.dtsi:481 */
			#address-cells = < 0x1 >;       /* in zephyr\dts\arm\nordic\nrf52833.dtsi:482 */
			#size-cells = < 0x0 >;          /* in zephyr\dts\arm\nordic\nrf52833.dtsi:483 */
			reg = < 0x40023000 0x1000 >;    /* in zephyr\dts\arm\nordic\nrf52833.dtsi:484 */
			interrupts = < 0x23 0x1 >;      /* in zephyr\dts\arm\nordic\nrf52833.dtsi:485 */
			max-frequency = < 0x7a1200 >;   /* in zephyr\dts\arm\nordic\nrf52833.dtsi:486 */
			easydma-maxcnt-bits = < 0x10 >; /* in zephyr\dts\arm\nordic\nrf52833.dtsi:487 */
			status = "disabled";            /* in zephyr\dts\arm\nordic\nrf52833.dtsi:488 */
		};

		/* node '/soc/rtc@40024000' defined in zephyr\dts\arm\nordic\nrf52833.dtsi:491 */
		rtc2: rtc@40024000 {
			compatible = "nordic,nrf-rtc"; /* in zephyr\dts\arm\nordic\nrf52833.dtsi:492 */
			reg = < 0x40024000 0x1000 >;   /* in zephyr\dts\arm\nordic\nrf52833.dtsi:493 */
			cc-num = < 0x4 >;              /* in zephyr\dts\arm\nordic\nrf52833.dtsi:494 */
			interrupts = < 0x24 0x1 >;     /* in zephyr\dts\arm\nordic\nrf52833.dtsi:495 */
			status = "disabled";           /* in zephyr\dts\arm\nordic\nrf52833.dtsi:496 */
			clock-frequency = < 0x8000 >;  /* in zephyr\dts\arm\nordic\nrf52833.dtsi:497 */
			prescaler = < 0x1 >;           /* in zephyr\dts\arm\nordic\nrf52833.dtsi:498 */
		};

		/* node '/soc/i2s@40025000' defined in zephyr\dts\arm\nordic\nrf52833.dtsi:501 */
		i2s0: i2s@40025000 {
			compatible = "nordic,nrf-i2s"; /* in zephyr\dts\arm\nordic\nrf52833.dtsi:502 */
			#address-cells = < 0x1 >;      /* in zephyr\dts\arm\nordic\nrf52833.dtsi:503 */
			#size-cells = < 0x0 >;         /* in zephyr\dts\arm\nordic\nrf52833.dtsi:504 */
			reg = < 0x40025000 0x1000 >;   /* in zephyr\dts\arm\nordic\nrf52833.dtsi:505 */
			interrupts = < 0x25 0x1 >;     /* in zephyr\dts\arm\nordic\nrf52833.dtsi:506 */
			status = "disabled";           /* in zephyr\dts\arm\nordic\nrf52833.dtsi:507 */
		};

		/* node '/soc/usbd@40027000' defined in zephyr\dts\arm\nordic\nrf52833.dtsi:510 */
		usbd: zephyr_udc0: usbd@40027000 {
			reg = < 0x40027000 0x1000 >;    /* in zephyr\dts\arm\nordic\nrf52833.dtsi:512 */
			interrupts = < 0x27 0x1 >;      /* in zephyr\dts\arm\nordic\nrf52833.dtsi:513 */
			num-bidir-endpoints = < 0x1 >;  /* in zephyr\dts\arm\nordic\nrf52833.dtsi:514 */
			num-in-endpoints = < 0x7 >;     /* in zephyr\dts\arm\nordic\nrf52833.dtsi:515 */
			num-out-endpoints = < 0x7 >;    /* in zephyr\dts\arm\nordic\nrf52833.dtsi:516 */
			num-isoin-endpoints = < 0x1 >;  /* in zephyr\dts\arm\nordic\nrf52833.dtsi:517 */
			num-isoout-endpoints = < 0x1 >; /* in zephyr\dts\arm\nordic\nrf52833.dtsi:518 */
			compatible = "nordic,nrf-usbd"; /* in F:/nRF-Firmware-DqEdit/SlimeVR-Tracker-nRF/boards/nekumori/sakuranrf/sakuranrf_uf2.dts:187 */
			status = "okay";                /* in F:/nRF-Firmware-DqEdit/SlimeVR-Tracker-nRF/boards/nekumori/sakuranrf/sakuranrf_uf2.dts:188 */

			/* node '/soc/usbd@40027000/cdc_acm_uart0' defined in F:/nRF-Firmware-DqEdit/SlimeVR-Tracker-nRF/boards/nekumori/sakuranrf/sakuranrf_uf2.dts:189 */
			cdc_acm_uart0: cdc_acm_uart0 {
				compatible = "zephyr,cdc-acm-uart"; /* in F:/nRF-Firmware-DqEdit/SlimeVR-Tracker-nRF/boards/nekumori/sakuranrf/sakuranrf_uf2.dts:190 */
			};
		};

		/* node '/soc/uart@40028000' defined in zephyr\dts\arm\nordic\nrf52833.dtsi:522 */
		uart1: uart@40028000 {
			compatible = "nordic,nrf-uarte"; /* in zephyr\dts\arm\nordic\nrf52833.dtsi:523 */
			reg = < 0x40028000 0x1000 >;     /* in zephyr\dts\arm\nordic\nrf52833.dtsi:524 */
			interrupts = < 0x28 0x1 >;       /* in zephyr\dts\arm\nordic\nrf52833.dtsi:525 */
			status = "disabled";             /* in zephyr\dts\arm\nordic\nrf52833.dtsi:526 */
		};

		/* node '/soc/pwm@4002d000' defined in zephyr\dts\arm\nordic\nrf52833.dtsi:529 */
		pwm3: pwm@4002d000 {
			compatible = "nordic,nrf-pwm"; /* in zephyr\dts\arm\nordic\nrf52833.dtsi:530 */
			reg = < 0x4002d000 0x1000 >;   /* in zephyr\dts\arm\nordic\nrf52833.dtsi:531 */
			interrupts = < 0x2d 0x1 >;     /* in zephyr\dts\arm\nordic\nrf52833.dtsi:532 */
			status = "disabled";           /* in zephyr\dts\arm\nordic\nrf52833.dtsi:533 */
			#pwm-cells = < 0x3 >;          /* in zephyr\dts\arm\nordic\nrf52833.dtsi:534 */
		};

		/* node '/soc/spi@4002f000' defined in zephyr\dts\arm\nordic\nrf52833.dtsi:537 */
		spi3: spi@4002f000 {
			#address-cells = < 0x1 >;       /* in zephyr\dts\arm\nordic\nrf52833.dtsi:539 */
			#size-cells = < 0x0 >;          /* in zephyr\dts\arm\nordic\nrf52833.dtsi:540 */
			reg = < 0x4002f000 0x1000 >;    /* in zephyr\dts\arm\nordic\nrf52833.dtsi:541 */
			interrupts = < 0x2f 0x1 >;      /* in zephyr\dts\arm\nordic\nrf52833.dtsi:542 */
			easydma-maxcnt-bits = < 0x10 >; /* in zephyr\dts\arm\nordic\nrf52833.dtsi:544 */
			rx-delay-supported;             /* in zephyr\dts\arm\nordic\nrf52833.dtsi:545 */
			rx-delay = < 0x2 >;             /* in zephyr\dts\arm\nordic\nrf52833.dtsi:546 */
			compatible = "nordic,nrf-spim"; /* in F:/nRF-Firmware-DqEdit/SlimeVR-Tracker-nRF/boards/nekumori/sakuranrf/sakuranrf_uf2.dts:203 */
			status = "okay";                /* in F:/nRF-Firmware-DqEdit/SlimeVR-Tracker-nRF/boards/nekumori/sakuranrf/sakuranrf_uf2.dts:204 */
			max-frequency = < 0x16e3600 >;  /* in F:/nRF-Firmware-DqEdit/SlimeVR-Tracker-nRF/boards/nekumori/sakuranrf/sakuranrf_uf2.dts:205 */
			pinctrl-0 = < &spi3_default >;  /* in F:/nRF-Firmware-DqEdit/SlimeVR-Tracker-nRF/boards/nekumori/sakuranrf/sakuranrf_uf2.dts:206 */
			pinctrl-1 = < &spi3_sleep >;    /* in F:/nRF-Firmware-DqEdit/SlimeVR-Tracker-nRF/boards/nekumori/sakuranrf/sakuranrf_uf2.dts:207 */
			pinctrl-names = "default",
			                "sleep";        /* in F:/nRF-Firmware-DqEdit/SlimeVR-Tracker-nRF/boards/nekumori/sakuranrf/sakuranrf_uf2.dts:208 */
			cs-gpios = < &gpio0 0x16 0x1 >; /* in F:/nRF-Firmware-DqEdit/SlimeVR-Tracker-nRF/boards/nekumori/sakuranrf/sakuranrf_uf2.dts:209 */

			/* node '/soc/spi@4002f000/imu_spi@0' defined in F:/nRF-Firmware-DqEdit/SlimeVR-Tracker-nRF/boards/nekumori/sakuranrf/sakuranrf_uf2.dts:211 */
			imu_spi: imu_spi@0 {
				compatible = "vnd,spi-device";     /* in F:/nRF-Firmware-DqEdit/SlimeVR-Tracker-nRF/boards/nekumori/sakuranrf/sakuranrf_uf2.dts:212 */
				spi-max-frequency = < 0x16e3600 >; /* in F:/nRF-Firmware-DqEdit/SlimeVR-Tracker-nRF/boards/nekumori/sakuranrf/sakuranrf_uf2.dts:213 */
				label = "imu-spi";                 /* in F:/nRF-Firmware-DqEdit/SlimeVR-Tracker-nRF/boards/nekumori/sakuranrf/sakuranrf_uf2.dts:214 */
				reg = < 0x0 >;                     /* in F:/nRF-Firmware-DqEdit/SlimeVR-Tracker-nRF/boards/nekumori/sakuranrf/sakuranrf_uf2.dts:215 */
			};
		};

		/* node '/soc/gpio@50000000' defined in zephyr\dts\arm\nordic\nrf52833.dtsi:550 */
		gpio0: gpio@50000000 {
			compatible = "nordic,nrf-gpio";              /* in zephyr\dts\arm\nordic\nrf52833.dtsi:551 */
			gpio-controller;                             /* in zephyr\dts\arm\nordic\nrf52833.dtsi:552 */
			reg = < 0x50000000 0x200 0x50000500 0x300 >; /* in zephyr\dts\arm\nordic\nrf52833.dtsi:553 */
			#gpio-cells = < 0x2 >;                       /* in zephyr\dts\arm\nordic\nrf52833.dtsi:555 */
			port = < 0x0 >;                              /* in zephyr\dts\arm\nordic\nrf52833.dtsi:557 */
			gpiote-instance = < &gpiote >;               /* in zephyr\dts\arm\nordic\nrf52833.dtsi:558 */
			status = "okay";                             /* in F:/nRF-Firmware-DqEdit/SlimeVR-Tracker-nRF/boards/nekumori/sakuranrf/sakuranrf_uf2.dts:141 */
			phandle = < 0x8 >;                           /* in F:/nRF-Firmware-DqEdit/SlimeVR-Tracker-nRF/boards/nekumori/sakuranrf/sakuranrf_uf2.dts:209 */
		};

		/* node '/soc/gpio@50000300' defined in zephyr\dts\arm\nordic\nrf52833.dtsi:561 */
		gpio1: gpio@50000300 {
			compatible = "nordic,nrf-gpio";              /* in zephyr\dts\arm\nordic\nrf52833.dtsi:562 */
			gpio-controller;                             /* in zephyr\dts\arm\nordic\nrf52833.dtsi:563 */
			reg = < 0x50000300 0x200 0x50000800 0x300 >; /* in zephyr\dts\arm\nordic\nrf52833.dtsi:564 */
			#gpio-cells = < 0x2 >;                       /* in zephyr\dts\arm\nordic\nrf52833.dtsi:566 */
			ngpios = < 0xa >;                            /* in zephyr\dts\arm\nordic\nrf52833.dtsi:567 */
			port = < 0x1 >;                              /* in zephyr\dts\arm\nordic\nrf52833.dtsi:569 */
			gpiote-instance = < &gpiote >;               /* in zephyr\dts\arm\nordic\nrf52833.dtsi:570 */
			status = "okay";                             /* in F:/nRF-Firmware-DqEdit/SlimeVR-Tracker-nRF/boards/nekumori/sakuranrf/sakuranrf_uf2.dts:145 */
			phandle = < 0xc >;                           /* in F:/nRF-Firmware-DqEdit/SlimeVR-Tracker-nRF/boards/nekumori/sakuranrf/sakuranrf_uf2.dts:91 */
		};
	};

	/* node '/pin-controller' defined in zephyr\dts\vendor\nordic\nrf_common.dtsi:26 */
	pinctrl: pin-controller {
		compatible = "nordic,nrf-pinctrl"; /* in zephyr\dts\vendor\nordic\nrf_common.dtsi:31 */

		/* node '/pin-controller/i2c0_default' defined in F:/nRF-Firmware-DqEdit/SlimeVR-Tracker-nRF/boards/nekumori/sakuranrf/sakuranrf_uf2.dts:9 */
		i2c0_default: i2c0_default {

			/* node '/pin-controller/i2c0_default/group1' defined in F:/nRF-Firmware-DqEdit/SlimeVR-Tracker-nRF/boards/nekumori/sakuranrf/sakuranrf_uf2.dts:10 */
			group1 {
				psels = < 0xc000006 >,
				        < 0xb000008 >; /* in F:/nRF-Firmware-DqEdit/SlimeVR-Tracker-nRF/boards/nekumori/sakuranrf/sakuranrf_uf2.dts:11 */
				bias-disable;          /* in F:/nRF-Firmware-DqEdit/SlimeVR-Tracker-nRF/boards/nekumori/sakuranrf/sakuranrf_uf2.dts:12 */
			};
		};

		/* node '/pin-controller/i2c0_sleep' defined in F:/nRF-Firmware-DqEdit/SlimeVR-Tracker-nRF/boards/nekumori/sakuranrf/sakuranrf_uf2.dts:16 */
		i2c0_sleep: i2c0_sleep {

			/* node '/pin-controller/i2c0_sleep/group1' defined in F:/nRF-Firmware-DqEdit/SlimeVR-Tracker-nRF/boards/nekumori/sakuranrf/sakuranrf_uf2.dts:17 */
			group1 {
				psels = < 0xc000006 >,
				        < 0xb000008 >; /* in F:/nRF-Firmware-DqEdit/SlimeVR-Tracker-nRF/boards/nekumori/sakuranrf/sakuranrf_uf2.dts:18 */
				bias-disable;          /* in F:/nRF-Firmware-DqEdit/SlimeVR-Tracker-nRF/boards/nekumori/sakuranrf/sakuranrf_uf2.dts:19 */
				low-power-enable;      /* in F:/nRF-Firmware-DqEdit/SlimeVR-Tracker-nRF/boards/nekumori/sakuranrf/sakuranrf_uf2.dts:20 */
			};
		};

		/* node '/pin-controller/pwm0_default' defined in F:/nRF-Firmware-DqEdit/SlimeVR-Tracker-nRF/boards/nekumori/sakuranrf/sakuranrf_uf2.dts:24 */
		pwm0_default: pwm0_default {
			phandle = < 0x2 >; /* in F:/nRF-Firmware-DqEdit/SlimeVR-Tracker-nRF/boards/nekumori/sakuranrf/sakuranrf_uf2.dts:174 */

			/* node '/pin-controller/pwm0_default/group1' defined in F:/nRF-Firmware-DqEdit/SlimeVR-Tracker-nRF/boards/nekumori/sakuranrf/sakuranrf_uf2.dts:25 */
			group1 {
				psels = < 0x16000002 >,
				        < 0x1700002f >,
				        < 0x1800001d >;      /* in F:/nRF-Firmware-DqEdit/SlimeVR-Tracker-nRF/boards/nekumori/sakuranrf/sakuranrf_uf2_chrysalis.dts:9 */
				nordic,drive-mode = < 0x0 >; /* in F:/nRF-Firmware-DqEdit/SlimeVR-Tracker-nRF/boards/nekumori/sakuranrf/sakuranrf_uf2_chrysalis.dts:12 */
				nordic,invert;               /* in F:/nRF-Firmware-DqEdit/SlimeVR-Tracker-nRF/boards/nekumori/sakuranrf/sakuranrf_uf2_chrysalis.dts:13 */
			};
		};

		/* node '/pin-controller/pwm0_sleep' defined in F:/nRF-Firmware-DqEdit/SlimeVR-Tracker-nRF/boards/nekumori/sakuranrf/sakuranrf_uf2.dts:31 */
		pwm0_sleep: pwm0_sleep {
			phandle = < 0x3 >; /* in F:/nRF-Firmware-DqEdit/SlimeVR-Tracker-nRF/boards/nekumori/sakuranrf/sakuranrf_uf2.dts:175 */

			/* node '/pin-controller/pwm0_sleep/group1' defined in F:/nRF-Firmware-DqEdit/SlimeVR-Tracker-nRF/boards/nekumori/sakuranrf/sakuranrf_uf2.dts:32 */
			group1 {
				psels = < 0x16000002 >,
				        < 0x1700002f >,
				        < 0x1800001d >; /* in F:/nRF-Firmware-DqEdit/SlimeVR-Tracker-nRF/boards/nekumori/sakuranrf/sakuranrf_uf2_chrysalis.dts:19 */
				low-power-enable;       /* in F:/nRF-Firmware-DqEdit/SlimeVR-Tracker-nRF/boards/nekumori/sakuranrf/sakuranrf_uf2_chrysalis.dts:22 */
			};
		};

		/* node '/pin-controller/pwm1_default' defined in F:/nRF-Firmware-DqEdit/SlimeVR-Tracker-nRF/boards/nekumori/sakuranrf/sakuranrf_uf2.dts:38 */
		pwm1_default: pwm1_default {
			phandle = < 0x4 >; /* in F:/nRF-Firmware-DqEdit/SlimeVR-Tracker-nRF/boards/nekumori/sakuranrf/sakuranrf_uf2.dts:181 */

			/* node '/pin-controller/pwm1_default/group1' defined in F:/nRF-Firmware-DqEdit/SlimeVR-Tracker-nRF/boards/nekumori/sakuranrf/sakuranrf_uf2.dts:39 */
			group1 {
				psels = < 0x1ff >; /* in F:/nRF-Firmware-DqEdit/SlimeVR-Tracker-nRF/boards/nekumori/sakuranrf/sakuranrf_uf2.dts:40 */
			};
		};

		/* node '/pin-controller/pwm1_sleep' defined in F:/nRF-Firmware-DqEdit/SlimeVR-Tracker-nRF/boards/nekumori/sakuranrf/sakuranrf_uf2.dts:44 */
		pwm1_sleep: pwm1_sleep {
			phandle = < 0x5 >; /* in F:/nRF-Firmware-DqEdit/SlimeVR-Tracker-nRF/boards/nekumori/sakuranrf/sakuranrf_uf2.dts:182 */

			/* node '/pin-controller/pwm1_sleep/group1' defined in F:/nRF-Firmware-DqEdit/SlimeVR-Tracker-nRF/boards/nekumori/sakuranrf/sakuranrf_uf2.dts:45 */
			group1 {
				psels = < 0x1ff >; /* in F:/nRF-Firmware-DqEdit/SlimeVR-Tracker-nRF/boards/nekumori/sakuranrf/sakuranrf_uf2.dts:46 */
				low-power-enable;  /* in F:/nRF-Firmware-DqEdit/SlimeVR-Tracker-nRF/boards/nekumori/sakuranrf/sakuranrf_uf2.dts:47 */
			};
		};

		/* node '/pin-controller/spi3_default' defined in F:/nRF-Firmware-DqEdit/SlimeVR-Tracker-nRF/boards/nekumori/sakuranrf/sakuranrf_uf2.dts:51 */
		spi3_default: spi3_default {
			phandle = < 0x6 >; /* in F:/nRF-Firmware-DqEdit/SlimeVR-Tracker-nRF/boards/nekumori/sakuranrf/sakuranrf_uf2.dts:206 */

			/* node '/pin-controller/spi3_default/group1' defined in F:/nRF-Firmware-DqEdit/SlimeVR-Tracker-nRF/boards/nekumori/sakuranrf/sakuranrf_uf2.dts:52 */
			group1 {
				psels = < 0x6000018 >,
				        < 0x5000006 >,
				        < 0x4000008 >; /* in F:/nRF-Firmware-DqEdit/SlimeVR-Tracker-nRF/boards/nekumori/sakuranrf/sakuranrf_uf2.dts:53 */
			};
		};

		/* node '/pin-controller/spi3_sleep' defined in F:/nRF-Firmware-DqEdit/SlimeVR-Tracker-nRF/boards/nekumori/sakuranrf/sakuranrf_uf2.dts:59 */
		spi3_sleep: spi3_sleep {
			phandle = < 0x7 >; /* in F:/nRF-Firmware-DqEdit/SlimeVR-Tracker-nRF/boards/nekumori/sakuranrf/sakuranrf_uf2.dts:207 */

			/* node '/pin-controller/spi3_sleep/group1' defined in F:/nRF-Firmware-DqEdit/SlimeVR-Tracker-nRF/boards/nekumori/sakuranrf/sakuranrf_uf2.dts:60 */
			group1 {
				psels = < 0x6000018 >,
				        < 0x5000006 >,
				        < 0x4000008 >; /* in F:/nRF-Firmware-DqEdit/SlimeVR-Tracker-nRF/boards/nekumori/sakuranrf/sakuranrf_uf2.dts:61 */
				low-power-enable;      /* in F:/nRF-Firmware-DqEdit/SlimeVR-Tracker-nRF/boards/nekumori/sakuranrf/sakuranrf_uf2.dts:64 */
			};
		};
	};

	/* node '/entropy_bt_hci' defined in zephyr\dts\vendor\nordic\nrf_common.dtsi:34 */
	rng_hci: entropy_bt_hci {
		compatible = "zephyr,bt-hci-entropy"; /* in zephyr\dts\vendor\nordic\nrf_common.dtsi:35 */
		status = "disabled";                  /* in zephyr\dts\vendor\nordic\nrf_common.dtsi:36 */
	};

	/* node '/sw-pwm' defined in zephyr\dts\vendor\nordic\nrf_common.dtsi:39 */
	sw_pwm: sw-pwm {
		compatible = "nordic,nrf-sw-pwm"; /* in zephyr\dts\vendor\nordic\nrf_common.dtsi:40 */
		status = "disabled";              /* in zephyr\dts\vendor\nordic\nrf_common.dtsi:41 */
		generator = < &timer1 >;          /* in zephyr\dts\vendor\nordic\nrf_common.dtsi:42 */
		clock-prescaler = < 0x0 >;        /* in zephyr\dts\vendor\nordic\nrf_common.dtsi:43 */
		#pwm-cells = < 0x3 >;             /* in zephyr\dts\vendor\nordic\nrf_common.dtsi:44 */
	};

	/* node '/cpus' defined in zephyr\dts\arm\nordic\nrf52833.dtsi:19 */
	cpus {
		#address-cells = < 0x1 >; /* in zephyr\dts\arm\nordic\nrf52833.dtsi:20 */
		#size-cells = < 0x0 >;    /* in zephyr\dts\arm\nordic\nrf52833.dtsi:21 */

		/* node '/cpus/cpu@0' defined in zephyr\dts\arm\nordic\nrf52833.dtsi:23 */
		cpu@0 {
			device_type = "cpu";           /* in zephyr\dts\arm\nordic\nrf52833.dtsi:24 */
			compatible = "arm,cortex-m4f"; /* in zephyr\dts\arm\nordic\nrf52833.dtsi:25 */
			reg = < 0x0 >;                 /* in zephyr\dts\arm\nordic\nrf52833.dtsi:26 */
			#address-cells = < 0x1 >;      /* in zephyr\dts\arm\nordic\nrf52833.dtsi:27 */
			#size-cells = < 0x1 >;         /* in zephyr\dts\arm\nordic\nrf52833.dtsi:28 */

			/* node '/cpus/cpu@0/itm@e0000000' defined in zephyr\dts\arm\nordic\nrf52833.dtsi:30 */
			itm: itm@e0000000 {
				compatible = "arm,armv7m-itm";     /* in zephyr\dts\arm\nordic\nrf52833.dtsi:31 */
				reg = < 0xe0000000 0x1000 >;       /* in zephyr\dts\arm\nordic\nrf52833.dtsi:32 */
				swo-ref-frequency = < 0x1e84800 >; /* in zephyr\dts\arm\nordic\nrf52833.dtsi:33 */
			};
		};
	};

	/* node '/clocks' defined in zephyr\dts\arm\nordic\nrf52833.dtsi:38 */
	clocks {

		/* node '/clocks/hfxo' defined in zephyr\dts\arm\nordic\nrf52833.dtsi:39 */
		hfxo: hfxo {
			compatible = "nordic,nrf52-hfxo"; /* in zephyr\dts\arm\nordic\nrf52833.dtsi:40 */
			clock-frequency = < 0x3d09000 >;  /* in zephyr\dts\arm\nordic\nrf52833.dtsi:41 */
			startup-time-us = < 0x578 >;      /* in zephyr\dts\arm\nordic\nrf52833.dtsi:42 */
			#clock-cells = < 0x0 >;           /* in zephyr\dts\arm\nordic\nrf52833.dtsi:43 */
		};
	};

	/* node '/pwmleds' defined in F:/nRF-Firmware-DqEdit/SlimeVR-Tracker-nRF/boards/nekumori/sakuranrf/sakuranrf_uf2.dts:81 */
	pwmleds {
		compatible = "pwm-leds"; /* in F:/nRF-Firmware-DqEdit/SlimeVR-Tracker-nRF/boards/nekumori/sakuranrf/sakuranrf_uf2.dts:82 */

		/* node '/pwmleds/pwm_led_0' defined in F:/nRF-Firmware-DqEdit/SlimeVR-Tracker-nRF/boards/nekumori/sakuranrf/sakuranrf_uf2_chrysalis.dts:29 */
		pwm_led0: pwm_led_0 {
			pwms = < &pwm0 0x0 0xf4240 0x1 >; /* in F:/nRF-Firmware-DqEdit/SlimeVR-Tracker-nRF/boards/nekumori/sakuranrf/sakuranrf_uf2_chrysalis.dts:30 */
		};

		/* node '/pwmleds/pwm_led_1' defined in F:/nRF-Firmware-DqEdit/SlimeVR-Tracker-nRF/boards/nekumori/sakuranrf/sakuranrf_uf2_chrysalis.dts:32 */
		pwm_led1: pwm_led_1 {
			pwms = < &pwm0 0x1 0xf4240 0x1 >; /* in F:/nRF-Firmware-DqEdit/SlimeVR-Tracker-nRF/boards/nekumori/sakuranrf/sakuranrf_uf2_chrysalis.dts:33 */
		};

		/* node '/pwmleds/pwm_led_2' defined in F:/nRF-Firmware-DqEdit/SlimeVR-Tracker-nRF/boards/nekumori/sakuranrf/sakuranrf_uf2_chrysalis.dts:35 */
		pwm_led2: pwm_led_2 {
			pwms = < &pwm0 0x2 0xf4240 0x1 >; /* in F:/nRF-Firmware-DqEdit/SlimeVR-Tracker-nRF/boards/nekumori/sakuranrf/sakuranrf_uf2_chrysalis.dts:36 */
		};
	};

	/* node '/buttons' defined in F:/nRF-Firmware-DqEdit/SlimeVR-Tracker-nRF/boards/nekumori/sakuranrf/sakuranrf_uf2.dts:88 */
	buttons {
		compatible = "gpio-keys"; /* in F:/nRF-Firmware-DqEdit/SlimeVR-Tracker-nRF/boards/nekumori/sakuranrf/sakuranrf_uf2.dts:89 */

		/* node '/buttons/button_0' defined in F:/nRF-Firmware-DqEdit/SlimeVR-Tracker-nRF/boards/nekumori/sakuranrf/sakuranrf_uf2.dts:90 */
		button0: button_0 {
			gpios = < &gpio1 0x0 0x11 >;    /* in F:/nRF-Firmware-DqEdit/SlimeVR-Tracker-nRF/boards/nekumori/sakuranrf/sakuranrf_uf2.dts:91 */
			label = "Push button switch 0"; /* in F:/nRF-Firmware-DqEdit/SlimeVR-Tracker-nRF/boards/nekumori/sakuranrf/sakuranrf_uf2.dts:92 */
		};
	};

	/* node '/pwmclock' defined in F:/nRF-Firmware-DqEdit/SlimeVR-Tracker-nRF/boards/nekumori/sakuranrf/sakuranrf_uf2.dts:101 */
	pwmclock: pwmclock {
		compatible = "pwm-clock";        /* in F:/nRF-Firmware-DqEdit/SlimeVR-Tracker-nRF/boards/nekumori/sakuranrf/sakuranrf_uf2.dts:102 */
		#clock-cells = < 0x1 >;          /* in F:/nRF-Firmware-DqEdit/SlimeVR-Tracker-nRF/boards/nekumori/sakuranrf/sakuranrf_uf2.dts:103 */
		pwms = < &pwm1 0x0 0x7735 0x0 >; /* in F:/nRF-Firmware-DqEdit/SlimeVR-Tracker-nRF/boards/nekumori/sakuranrf/sakuranrf_uf2.dts:104 */
	};

	/* node '/battery-divider' defined in F:/nRF-Firmware-DqEdit/SlimeVR-Tracker-nRF/boards/nekumori/sakuranrf/sakuranrf_uf2.dts:107 */
	battery-divider {
		compatible = "voltage-divider"; /* in F:/nRF-Firmware-DqEdit/SlimeVR-Tracker-nRF/boards/nekumori/sakuranrf/sakuranrf_uf2.dts:108 */
		status = "okay";                /* in F:/nRF-Firmware-DqEdit/SlimeVR-Tracker-nRF/boards/nekumori/sakuranrf/sakuranrf_uf2.dts:109 */
		io-channels = < &adc 0xc >;     /* in F:/nRF-Firmware-DqEdit/SlimeVR-Tracker-nRF/boards/nekumori/sakuranrf/sakuranrf_uf2.dts:110 */
		output-ohms = < 0x1 >;          /* in F:/nRF-Firmware-DqEdit/SlimeVR-Tracker-nRF/boards/nekumori/sakuranrf/sakuranrf_uf2.dts:111 */
		full-ohms = < 0x5 >;            /* in F:/nRF-Firmware-DqEdit/SlimeVR-Tracker-nRF/boards/nekumori/sakuranrf/sakuranrf_uf2.dts:112 */
	};

	/* node '/zephyr,user' defined in F:/nRF-Firmware-DqEdit/SlimeVR-Tracker-nRF/boards/nekumori/sakuranrf/sakuranrf_uf2.dts:115 */
	zephyr,user {
		int0-gpios = < &gpio0 0x11 0x0 >; /* in F:/nRF-Firmware-DqEdit/SlimeVR-Tracker-nRF/boards/nekumori/sakuranrf/sakuranrf_uf2.dts:116 */
		vcc-gpios = < &gpio0 0x1f 0x0 >;  /* in F:/nRF-Firmware-DqEdit/SlimeVR-Tracker-nRF/boards/nekumori/sakuranrf/sakuranrf_uf2.dts:119 */
		clk-gpios = < &gpio0 0x14 0x6 >;  /* in F:/nRF-Firmware-DqEdit/SlimeVR-Tracker-nRF/boards/nekumori/sakuranrf/sakuranrf_uf2_chrysalis.dts:64 */
	};

	/* node '/leds' defined in F:/nRF-Firmware-DqEdit/SlimeVR-Tracker-nRF/boards/nekumori/sakuranrf/sakuranrf_uf2_chrysalis.dts:40 */
	leds {
		compatible = "gpio-leds"; /* in F:/nRF-Firmware-DqEdit/SlimeVR-Tracker-nRF/boards/nekumori/sakuranrf/sakuranrf_uf2_chrysalis.dts:41 */

		/* node '/leds/led_0' defined in F:/nRF-Firmware-DqEdit/SlimeVR-Tracker-nRF/boards/nekumori/sakuranrf/sakuranrf_uf2_chrysalis.dts:42 */
		led0: led_0 {
			gpios = < &gpio0 0x2 0x1 >; /* in F:/nRF-Firmware-DqEdit/SlimeVR-Tracker-nRF/boards/nekumori/sakuranrf/sakuranrf_uf2_chrysalis.dts:43 */
		};

		/* node '/leds/led_1' defined in F:/nRF-Firmware-DqEdit/SlimeVR-Tracker-nRF/boards/nekumori/sakuranrf/sakuranrf_uf2_chrysalis.dts:45 */
		led1: led_1 {
			gpios = < &gpio1 0xf 0x1 >; /* in F:/nRF-Firmware-DqEdit/SlimeVR-Tracker-nRF/boards/nekumori/sakuranrf/sakuranrf_uf2_chrysalis.dts:46 */
		};

		/* node '/leds/led_2' defined in F:/nRF-Firmware-DqEdit/SlimeVR-Tracker-nRF/boards/nekumori/sakuranrf/sakuranrf_uf2_chrysalis.dts:48 */
		led2: led_2 {
			gpios = < &gpio0 0x1d 0x1 >; /* in F:/nRF-Firmware-DqEdit/SlimeVR-Tracker-nRF/boards/nekumori/sakuranrf/sakuranrf_uf2_chrysalis.dts:49 */
		};
	};

	/* node '/sram0@2003f000' defined in F:/nRF-Firmware-DqEdit/SlimeVR-Tracker-nRF/socs/nrf52833_chrysalis.overlay:2 */
	sram0@2003f000 {
		compatible = "zephyr,memory-region",
		             "mmio-sram";              /* in F:/nRF-Firmware-DqEdit/SlimeVR-Tracker-nRF/socs/nrf52833_chrysalis.overlay:3 */
		reg = < 0x2003f000 0x1000 >;           /* in F:/nRF-Firmware-DqEdit/SlimeVR-Tracker-nRF/socs/nrf52833_chrysalis.overlay:4 */
		zephyr,memory-region = "RETAINED_MEM"; /* in F:/nRF-Firmware-DqEdit/SlimeVR-Tracker-nRF/socs/nrf52833_chrysalis.overlay:5 */
		status = "okay";                       /* in F:/nRF-Firmware-DqEdit/SlimeVR-Tracker-nRF/socs/nrf52833_chrysalis.overlay:6 */

		/* node '/sram0@2003f000/retainedmem' defined in F:/nRF-Firmware-DqEdit/SlimeVR-Tracker-nRF/socs/nrf52833_chrysalis.overlay:8 */
		retainedmem0: retainedmem {
			compatible = "zephyr,retained-ram"; /* in F:/nRF-Firmware-DqEdit/SlimeVR-Tracker-nRF/socs/nrf52833_chrysalis.overlay:9 */
			status = "okay";                    /* in F:/nRF-Firmware-DqEdit/SlimeVR-Tracker-nRF/socs/nrf52833_chrysalis.overlay:10 */
		};
	};

	/* node '/sram0@20007f7c' defined in F:/nRF-Firmware-DqEdit/SlimeVR-Tracker-nRF/socs/nrf52833_chrysalis.overlay:14 */
	sram0@20007f7c {
		compatible = "zephyr,memory-region",
		             "mmio-sram";                   /* in F:/nRF-Firmware-DqEdit/SlimeVR-Tracker-nRF/socs/nrf52833_chrysalis.overlay:15 */
		reg = < 0x20007f7c 0x4 >;                   /* in F:/nRF-Firmware-DqEdit/SlimeVR-Tracker-nRF/socs/nrf52833_chrysalis.overlay:16 */
		zephyr,memory-region = "DFU_DBL_RESET_MEM"; /* in F:/nRF-Firmware-DqEdit/SlimeVR-Tracker-nRF/socs/nrf52833_chrysalis.overlay:17 */
		status = "okay";                            /* in F:/nRF-Firmware-DqEdit/SlimeVR-Tracker-nRF/socs/nrf52833_chrysalis.overlay:18 */

		/* node '/sram0@20007f7c/retainedmem' defined in F:/nRF-Firmware-DqEdit/SlimeVR-Tracker-nRF/socs/nrf52833_chrysalis.overlay:20 */
		retainedmem {
			compatible = "zephyr,retained-ram"; /* in F:/nRF-Firmware-DqEdit/SlimeVR-Tracker-nRF/socs/nrf52833_chrysalis.overlay:21 */
			status = "okay";                    /* in F:/nRF-Firmware-DqEdit/SlimeVR-Tracker-nRF/socs/nrf52833_chrysalis.overlay:22 */
		};
	};
};
